# CY8C5888LTI_LP097 register map
File version: 0.1
CY8C58LP
Registers are 8-bit, read-write, no defined reset value unless marked. A register's access mark holds for its fields unless they carry their own. Offsets are from the block's base; lines under a group give offsets from that group; [hi:lo] are bit positions; {n}, {i} and the like mark numbered series; 'fields as' and 'values as' point back to an identical list; <NAME> marks a mode.

## Memory map
0x00000000 UART_MOVI — UART
0x00000000 UART_MONITOR — UART

## UART_MOVI — UART
Base 0x00000000
0x4000642B RX_UART_MOVI_RX_ADDRESS1 — RX Address1 Register
0x4000643B RX_UART_MOVI_RX_ADDRESS2 — RX Address2 Register
0x4000644B RX_UART_MOVI_RX_DATA — RX Data Register
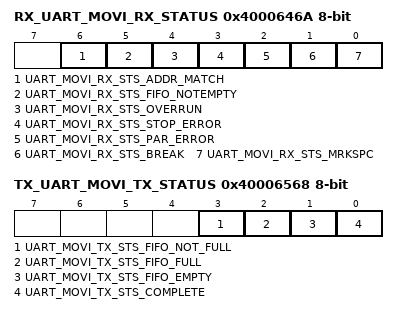
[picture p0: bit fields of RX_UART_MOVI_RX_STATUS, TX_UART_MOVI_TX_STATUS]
0x4000646A RX_UART_MOVI_RX_STATUS — RX status register
  [6] UART_MOVI_RX_STS_ADDR_MATCH ro, [5] UART_MOVI_RX_STS_FIFO_NOTEMPTY ro, [4] UART_MOVI_RX_STS_OVERRUN ro, [3] UART_MOVI_RX_STS_STOP_ERROR ro, [2] UART_MOVI_RX_STS_PAR_ERROR ro, [1] UART_MOVI_RX_STS_BREAK ro, [0] UART_MOVI_RX_STS_MRKSPC ro
0x40006548 TX_UART_MOVI_TX_DATA — TX Data Register
0x40006568 TX_UART_MOVI_TX_STATUS — TX status register
  [3] UART_MOVI_TX_STS_FIFO_NOT_FULL ro, [2] UART_MOVI_TX_STS_FIFO_FULL ro, [1] UART_MOVI_TX_STS_FIFO_EMPTY ro, [0] UART_MOVI_TX_STS_COMPLETE ro

## UART_MONITOR — UART
Base 0x00000000
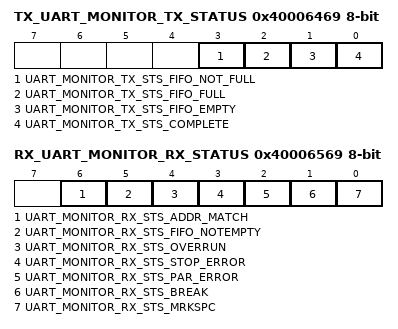
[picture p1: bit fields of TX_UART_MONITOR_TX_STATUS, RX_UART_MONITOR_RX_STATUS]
0x40006469 TX_UART_MONITOR_TX_STATUS — TX status register
  [3] UART_MONITOR_TX_STS_FIFO_NOT_FULL ro, [2] UART_MONITOR_TX_STS_FIFO_FULL ro, [1] UART_MONITOR_TX_STS_FIFO_EMPTY ro, [0] UART_MONITOR_TX_STS_COMPLETE ro
0x4000652A RX_UART_MONITOR_RX_ADDRESS1 — RX Address1 Register
0x4000653A RX_UART_MONITOR_RX_ADDRESS2 — RX Address2 Register
0x40006549 TX_UART_MONITOR_TX_DATA — TX Data Register
0x4000654A RX_UART_MONITOR_RX_DATA — RX Data Register
0x40006569 RX_UART_MONITOR_RX_STATUS — RX status register
  [6] UART_MONITOR_RX_STS_ADDR_MATCH ro, [5] UART_MONITOR_RX_STS_FIFO_NOTEMPTY ro, [4] UART_MONITOR_RX_STS_OVERRUN ro, [3] UART_MONITOR_RX_STS_STOP_ERROR ro, [2] UART_MONITOR_RX_STS_PAR_ERROR ro, [1] UART_MONITOR_RX_STS_BREAK ro, [0] UART_MONITOR_RX_STS_MRKSPC ro
